AUTOSAR XML (schema 4-3-0)
package /CollisionDetectionApplicationLayer/ApplicationPackage
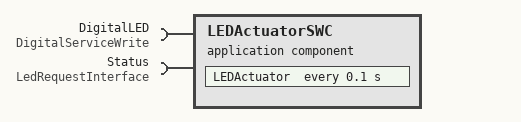
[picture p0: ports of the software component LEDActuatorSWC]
  application sw component type LEDActuatorSWC
    require port DigitalLED: required-interface=DigitalServiceWrite
    require port Status: required-interface=LedRequestInterface
    behavior LEDActuatorSWCBehaviour: data-type-mapping=TypeMappings, handle-termination-and-restart=NO-SUPPORT, supports-multiple-instantiation=true
      timing event LEDActuator_timingEvent_0_1: start-on-event=LEDActuator, period=0.1
      runnable LEDActuator: symbol=ledActuator
        data-read-access:
          access dataReadAccess_LEDActuator_Status_Status: accessed-variable=Status.Status
        sync call LEDCallPoint: operation=DigitalLED.Write, timeout=0.0
  swc implementation LEDActuatorSWCImpl: programming-language=C, vendor-id=0, behavior=LEDActuatorSWCBehaviour
    code-descriptors:
      code src: artifact-descriptors=autosar-engineering-object={short-label=artifactDescriptor, category=artifactDescriptorCategory}
    resource consumption resourceConsumption
